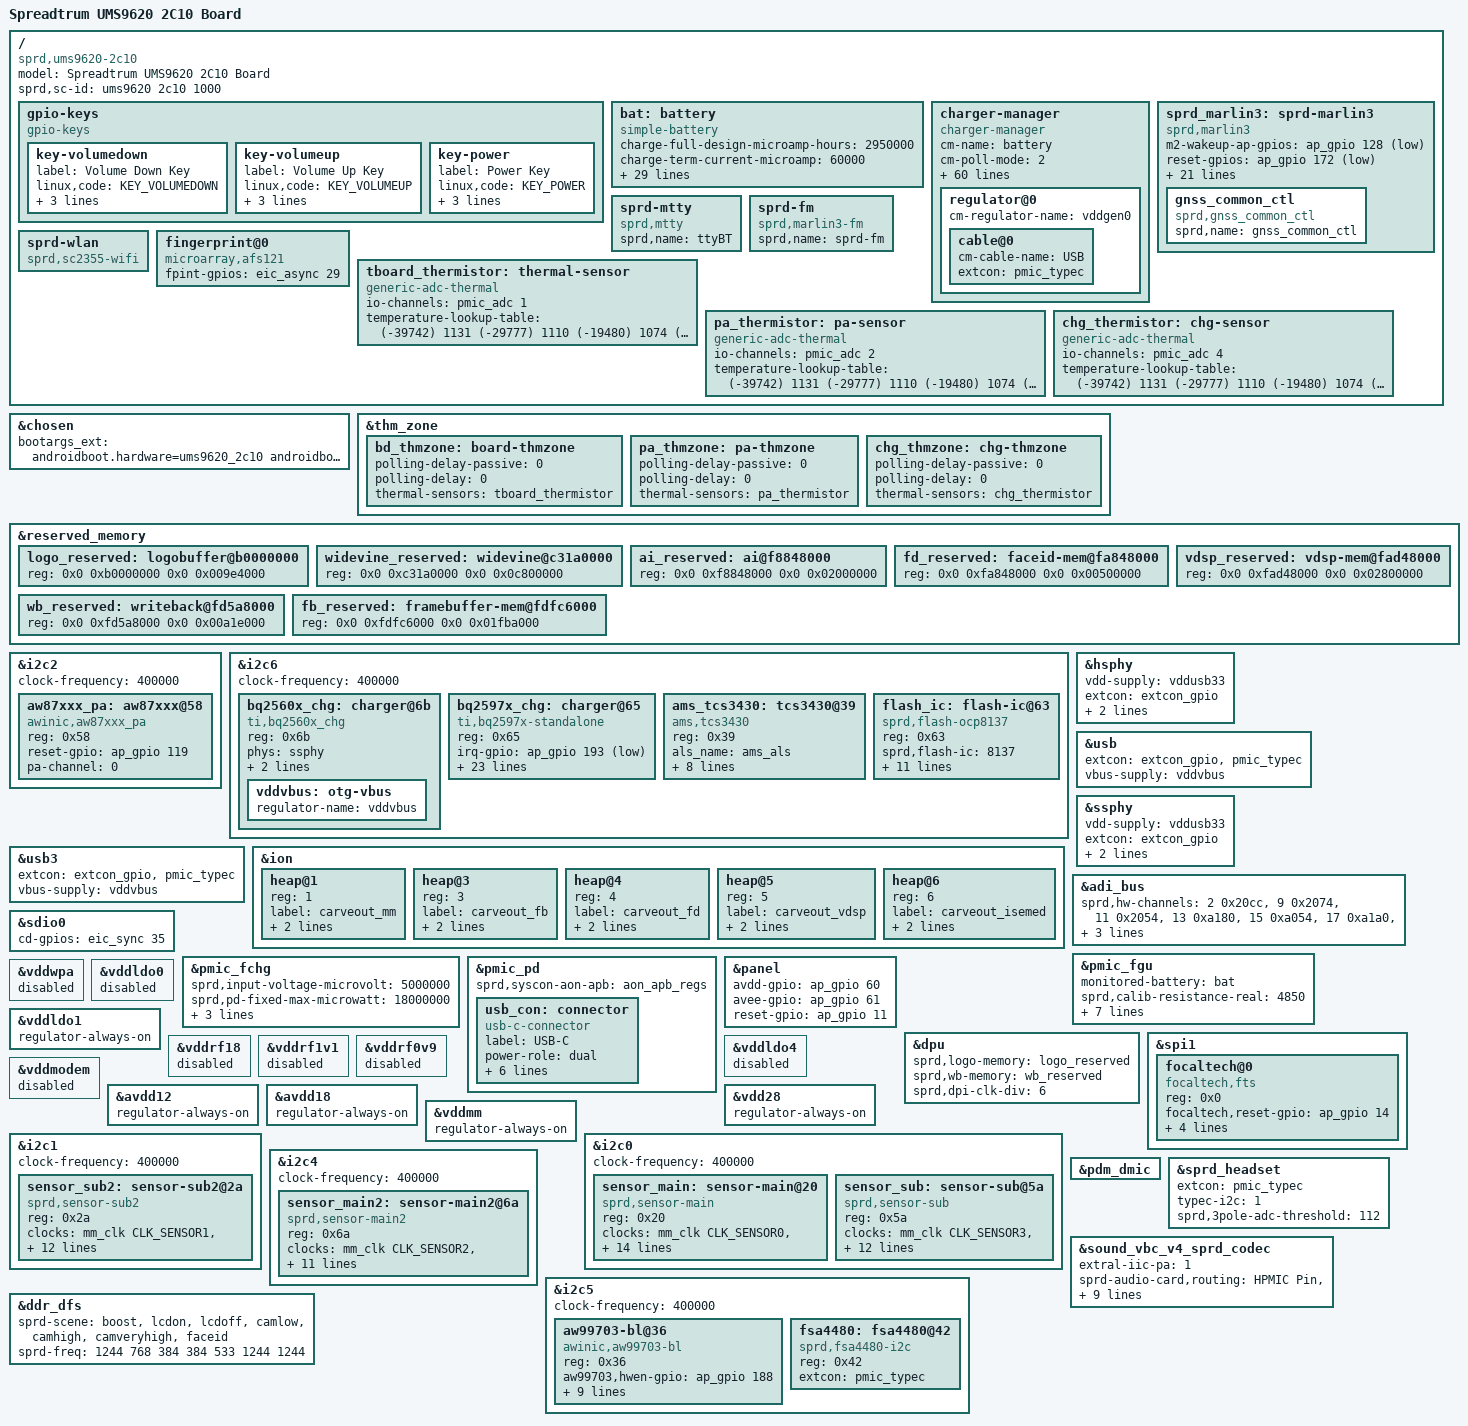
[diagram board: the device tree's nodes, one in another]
/dts-v1/;
/plugin/;
#include <dt-bindings/input/input.h>
#include <dt-bindings/gpio/gpio.h>
#include <dt-bindings/interrupt-controller/arm-gic.h>
#include <dt-bindings/clock/sprd,ums9620-clk.h>
#include <dt-bindings/usb/pd.h>
#include "lcd/lcd_ft8756_txd_mipi_hdplus.dtsi"
#include "lcd/lcd_jd9365t_cpt_mipi_hdp.dtsi"
#include "lcd/lcd_nl9911c_truly_mipi_hdp.dtsi"
#include "lcd/lcd_dummy_mipi.dtsi"
#include <dt-bindings/mfd/sprd,ump9620-regs.h>
#include <dt-bindings/mfd/sprd,ump9620-mask.h>
/ {

	model = "Spreadtrum UMS9620 2C10 Board";

	compatible = "sprd,ums9620-2c10";

	sprd,sc-id = "ums9620 2c10 1000";

	fragment {
		target-path = "/";
		__overlay__ {

			gpio-keys {
				compatible = "gpio-keys";

				key-volumedown {
					label = "Volume Down Key";
					linux,code = <KEY_VOLUMEDOWN>;
					gpios = <&ap_gpio 7 GPIO_ACTIVE_LOW>;
					debounce-interval = <2>;
					wakeup-source;
				};

				key-volumeup {
					label = "Volume Up Key";
					linux,code = <KEY_VOLUMEUP>;
					gpios = <&pmic_eic 4 GPIO_ACTIVE_HIGH>;
					debounce-interval = <2>;
					wakeup-source;
				};

				key-power {
					label = "Power Key";
					linux,code = <KEY_POWER>;
					gpios = <&pmic_eic 1 GPIO_ACTIVE_LOW>;
					debounce-interval = <2>;
					wakeup-source;
				};
			};

			bat: battery {
				compatible = "simple-battery";
				charge-full-design-microamp-hours = <2950000>;
				charge-term-current-microamp = <60000>;
				constant_charge_voltage_max_microvolt = <4340000>;
				factory-internal-resistance-micro-ohms = <252000>;
				voltage-min-design-microvolt = <3450000>;
				fast-charge-threshold-microvolt = <4100000>;
				ocv-capacity-celsius = <20>;
				ocv-capacity-table-0 = <4313000 100>, <4254000 95>, <4201000 90>,
							<4151000 85>, <4102000 80>, <4060000 75>,
							<4006000 70>, <3973000 65>, <3930000 60>,
							<3882000 55>, <3851000 50>, <3829000 45>,
							<3810000 40>, <3795000 35>, <3781000 30>,
							<3765000 25>, <3746000 20>, <3722000 15>,
							<3694000 10>, <3682000 5>, <3400000 0>;
				voltage-temp-table = <1084000 800>, <975000 850>, <868000 900>,
							  <765000 950>, <668000 1000>, <580000 1050>,
							  <501000 1100>, <430000 1150>, <369000 1200>,
							  <315000 1250>, <270000 1300>, <231000 1350>,
							  <197000 1400>, <169000 1450>, <145000 1500>,
							  <125000 1550>, <108000 1600>, <93000 1650>;
				capacity-temp-table = <45 100>, <25 100>, <10 100>, <0 95>, <(-10) 90>;
				resistance-temp-table = <45 53>, <25 100>, <10 395>, <0 567>, <(-10) 793>;
				charge-sdp-current-microamp = <500000 500000>;
				charge-dcp-current-microamp = <2000000 2500000>;
				charge-cdp-current-microamp = <1500000 1500000>;
				charge-unknown-current-microamp = <500000 500000>;
				charge-fchg-current-microamp = <3000000 2000000>;
				charge-flash-current-microamp = <5000000 2700000>;
			};

			charger-manager {
				compatible = "charger-manager";
				cm-name = "battery";
				cm-poll-mode = <2>;
				cm-poll-interval = <15000>;
				cm-battery-stat = <2>;

				cm-fullbatt-vchkdrop-ms = <30000>;
				cm-fullbatt-vchkdrop-volt = <60000>;
				cm-fullbatt-voltage = <4300000>;
				cm-fullbatt-current = <120000>;
				cm-fullbatt-capacity = <100>;
				/*Charge pump target charge current*/
				cm-cp-taper-current = <1000000>;

				cm-chargers = "bq2560x_charger";
				cm-charge-pumps = "bq2597x-standalone";
				cm-fast-chargers = "sc2730_fast_charger";
				cm-fuel-gauge = "sc27xx-fgu";

				/* in deci centigrade */
				cm-battery-cold = <200>;
				cm-battery-cold-in-minus;
				cm-battery-hot = <800>;
				cm-battery-temp-diff = <100>;

				/* Allow charging for 6hr */
				cm-charging-max = <21600000>;
				/* recovery charging after stop charging 45min */
				cm-discharging-max = <2700000>;

				/* the interval to feed charger watchdog */
				cm-wdt-interval = <60>;

				/* drop voltage in microVolts to allow shutdown */
				cm-shutdown-voltage = <3100000>;

				/* when 99% of the time is exceeded, it will be forced to 100% */
				cm-tickle-time-out = <1500>;

				/* how much time to allow capacity change */
				cm-one-cap-time = <30>;

				/* cm-thermal-zone = "board-thmzone"; */

				/* when the safe charging voltage is exceeded, stop charging */
				cm-charge-voltage-max = <6500000>;
				cm-fast-charge-voltage-max = <10500000>;
				cm-flash-charge-voltage-max = <12000000>;
				/* drop voltage in microVolts to restart charging */
				cm-charge-voltage-drop = <700000>;
				cm-fast-charge-voltage-drop = <700000>;
				cm-flash-charge-voltage-drop = <1000000>;

				cm-dcp-jeita-temp-table = <1000 1030 0 4340000>, <1150 1180 700000 4340000>,
					<1450 1420 2000000 4340000>, <1600 1570 700000 4100000>;
				cm-sdp-jeita-temp-table = <1000 1030 0 4340000>, <1150 1180 500000 4340000>,
					<1450 1420 500000 4340000>, <1600 1570 500000 4100000>;
				cm-cdp-jeita-temp-table = <1000 1030 0 4340000>, <1150 1180 700000 4340000>,
					<1450 1420 1500000 4340000>, <1600 1570 700000 4100000>;
				cm-unknown-jeita-temp-table = <1000 1030 0 4340000>, <1150 1180 500000 4340000>,
					<1450 1420 500000 4340000>, <1600 1570 500000 4100000>;
				cm-fchg-jeita-temp-table = <1000 1030 0 4340000>, <1150 1180 700000 4340000>,
					<1450 1420 3250000 4340000>, <1600 1570 700000 4100000>;
				cm-flash-jeita-temp-table = <1000 1030 0 4340000>, <1150 1180 1000000 4340000>,
					<1450 1420 5000000 4340000>, <1600 1570 1000000 4100000>;

				cm-cap-remap-table = <1 2 3>, <2 3 2>, <98 99 2>, <99 100 3>;

				monitored-battery = <&bat>;

				cm-ir-cv-offset-microvolt = <100000>;
				cm-ir-rc = <20>;
				cm-ir-us-upper-limit-microvolt = <4500000>;

				regulator@0 {
					cm-regulator-name = "vddgen0";
					cable@0 {
						cm-cable-name = "USB";
						extcon = <&pmic_typec>;
					};
				};
			};

			sprd_marlin3: sprd-marlin3 {
				compatible = "sprd,marlin3";
				m2-wakeup-ap-gpios = <&ap_gpio 128 GPIO_ACTIVE_LOW>;
				reset-gpios = <&ap_gpio 172 GPIO_ACTIVE_LOW>;
				enable-gpios = <&ap_gpio 171 GPIO_ACTIVE_LOW>;
				m2-to-ap-irq-gpios = <&ap_gpio 173 GPIO_ACTIVE_LOW>;
				xtal-26m-clk-type = "TCXO";
				avdd12-supply = <&vddwcn>;
				avdd33-supply = <&vddwifipa>;
				dcxo18-supply = <&vddsim2>;

				clock-names = "clk_32k","source","enable";
				clocks = <&aonapb_gate CLK_AUX0>,
					 <&ext_32k>,
					 <&aonapb_gate CLK_AUX0_EB>;

				sdhci-name = <&sdio1>;
				sprd,btwf-file-name = "/dev/block/by-name/wcnmodem";
				sprd,gnss-file-name = "/dev/block/by-name/gnssmodem";
				adma-tx;
				adma-rx;
				/*
				 * bound parameter:
				 * [0]:addr offset, [1]:mask, [2]:unboundval, [3]:boundval
				 */
				avdd12-parent-bound-chip = <REG_ANA_SLP_DCDC_PD_CTRL MASK_ANA_SLP_DCDCGEN1_PD_EN 0x0 MASK_ANA_SLP_DCDCGEN1_PD_EN>;
				avdd12-bound-wbreq = <REG_ANA_LDO_XTL_EN10 MASK_ANA_LDO_VDDWCN_EXT_XTL3_EN 0x0 MASK_ANA_LDO_VDDWCN_EXT_XTL3_EN>;
				avdd33-bound-wbreq = <REG_ANA_LDO_XTL_EN11 MASK_ANA_LDO_VDDWIFIPA_EXT_XTL3_EN 0x0 MASK_ANA_LDO_VDDWIFIPA_EXT_XTL3_EN>;

				gnss_common_ctl {
					compatible = "sprd,gnss_common_ctl";
					sprd,name = "gnss_common_ctl";
				};
			};

			sprd-mtty {
				compatible = "sprd,mtty";
				sprd,name = "ttyBT";
			};

			sprd-fm {
				compatible = "sprd,marlin3-fm";
				sprd,name = "sprd-fm";
			};

			sprd-wlan{
				compatible = "sprd,sc2355-wifi";
			};

			fingerprint@0 {
				compatible = "microarray,afs121";
				fpint-gpios = <&eic_async 29 0>;
			};

			tboard_thermistor: thermal-sensor {
				compatible = "generic-adc-thermal";
				#thermal-sensor-cells = <0>;
				io-channels = <&pmic_adc 1>;
				io-channel-names = "sensor-channel";
				temperature-lookup-table = <
					(-39742) 1131
					(-29777) 1110
					(-19480) 1074
					(-4679) 983
					10110 838
					24805 654
					44922 413
					54903 316
					64895 238
					74884 178
					84883 133
					94883 100
					104880 75
					114889 57
					124872 43 >;
			};

			pa_thermistor: pa-sensor {
				compatible = "generic-adc-thermal";
				#thermal-sensor-cells = <0>;
				io-channels = <&pmic_adc 2>;
				io-channel-names = "sensor-channel";
				temperature-lookup-table = <
					(-39742) 1131
					(-29777) 1110
					(-19480) 1074
					(-4679) 983
					10110 838
					24805 654
					44922 413
					54903 316
					64895 238
					74884 178
					84883 133
					94883 100
					104880 75
					114889 57
					124872 43 >;
			};

			chg_thermistor: chg-sensor {
				compatible = "generic-adc-thermal";
				#thermal-sensor-cells = <0>;
				io-channels = <&pmic_adc 4>;
				io-channel-names = "sensor-channel";
				temperature-lookup-table = <
					(-39742) 1131
					(-29777) 1110
					(-19480) 1074
					(-4679) 983
					10110 838
					24805 654
					44922 413
					54903 316
					64895 238
					74884 178
					84883 133
					94883 100
					104880 75
					114889 57
					124872 43 >;
			};
		};
	};
};

&chosen {
	bootargs_ext = "androidboot.hardware=ums9620_2c10 androidboot.dtbo_idx=0";
};

&thm_zone {
	bd_thmzone: board-thmzone {
		polling-delay-passive = <0>;
		polling-delay = <0>;
		thermal-sensors = <&tboard_thermistor>;
	};

	pa_thmzone: pa-thmzone {
		polling-delay-passive = <0>;
		polling-delay = <0>;
		thermal-sensors = <&pa_thermistor>;
	};

	chg_thmzone: chg-thmzone {
		polling-delay-passive = <0>;
		polling-delay = <0>;
		thermal-sensors = <&chg_thermistor>;
	};
};

&reserved_memory {
	logo_reserved: logobuffer@b0000000 {
		reg = <0x0 0xb0000000 0x0 0x009e4000>;
	};

	widevine_reserved: widevine@c31a0000 {
		reg = <0x0 0xc31a0000 0x0 0x0c800000>;
	};

	ai_reserved: ai@f8848000 {
		reg = <0x0 0xf8848000 0x0 0x02000000>;
	};

	fd_reserved: faceid-mem@fa848000 {
		reg = <0x0 0xfa848000 0x0 0x00500000>;
	};

	vdsp_reserved: vdsp-mem@fad48000 {
		reg = <0x0 0xfad48000 0x0 0x02800000>;
	};

	wb_reserved: writeback@fd5a8000 {
		reg = <0x0 0xfd5a8000 0x0 0x00a1e000>;
	};

	fb_reserved: framebuffer-mem@fdfc6000 {
		reg = <0x0 0xfdfc6000 0x0 0x01fba000>;
	};
};

&i2c2 {
	status = "okay";
	clock-frequency = <400000>;

	aw87xxx_pa: aw87xxx@58 {
		compatible = "awinic,aw87xxx_pa";
		reg = <0x58>;
		reset-gpio = <&ap_gpio 119 GPIO_ACTIVE_HIGH>;
		pa-channel = <0>;
		status = "okay";
	};
};

&i2c6 {
	status = "okay";
	clock-frequency = <400000>;

	bq2560x_chg: charger@6b {
		compatible = "ti,bq2560x_chg";
		reg = <0x6b>;
		phys = <&ssphy>;
		monitored-battery = <&bat>;
		extcon = <&extcon_gpio>;
		vddvbus:otg-vbus {
			regulator-name = "vddvbus";
		};
	};

	bq2597x_chg: charger@65 {
		compatible = "ti,bq2597x-standalone";
		reg = <0x65>;
		irq-gpio = <&ap_gpio 193 GPIO_ACTIVE_LOW>;

		ti,bq2597x,bus-therm-disable = <1>;
		ti,bq2597x,regulation-disable = <1>;

		ti,bq2597x,bat-ovp-threshold = <4400>;
		ti,bq2597x,bat-ovp-alarm-threshold = <4340>;
		ti,bq2597x,bat-ocp-threshold = <5500>;
		ti,bq2597x,bat-ocp-alarm-threshold = <5000>;
		ti,bq2597x,bus-ovp-threshold = <11500>;
		ti,bq2597x,bus-ovp-alarm-threshold = <10500>;
		ti,bq2597x,bus-ocp-threshold = <3000>;
		ti,bq2597x,bus-ocp-alarm-threshold = <2700>;
		ti,bq2597x,bat-ucp-alarm-threshold = <1000>;
		ti,bq2597x,bat-therm-threshold = <0x15>;
		ti,bq2597x,bus-therm-threshold = <0x15>;
		ti,bq2597x,die-therm-threshold = <0xc8>;
		ti,bq2597x,ac-ovp-threshold = <11>;
		ti,bq2597x,sense-resistor-mohm = <5>;
		ti,bq2597x,adc-sample-bits = <13>;
		ti,bq2597x,ibat-regulation-threshold = <300>;
		ti,bq2597x,vbat-regulation-threshold = <100>;
		ti,bq2597x,vdrop-threshold = <400>;
		ti,bq2597x,vdrop-deglitch = <5000>;
		ti,bq2597x,ss-timeout = <100000>;
		ti,bq2597x,watchdog-timer = <30000>;
	};

	ams_tcs3430: tcs3430@39 {
		compatible = "ams,tcs3430";
		reg = <0x39>;
		als_name = "ams_als";
		persist = <0>;
		als_time_ms = <100>;
		als_gain = <64>;
		int_config = <0>;
		als_can_wake = <1>;
		irq_gpios = <60>;
		interrupt-parent = <&ap_gpio>;
		interrupts = <60 IRQ_TYPE_LEVEL_LOW>;
	};
};

&hsphy {
	vdd-supply = <&vddusb33>;
	extcon = <&extcon_gpio>;
	sprd,hsphy-device-eye-pattern = <0x067bd1c0>;
	sprd,hsphy-host-eye-pattern = <0x067bd1c0>;
	status = "okay";
};

&usb {
	extcon = <&extcon_gpio>, <&pmic_typec>;
	vbus-supply = <&vddvbus>;
	status = "okay";
};

&ssphy {
	vdd-supply = <&vddusb33>;
	extcon = <&extcon_gpio>;
	sprd,hsphy-device-eye-pattern = <0x067bd1c0>;
	sprd,hsphy-host-eye-pattern = <0x067bd1c0>;
	status = "okay";
};

&usb3 {
	extcon = <&extcon_gpio>, <&pmic_typec>;
	vbus-supply = <&vddvbus>;
	status = "okay";
};

&ion {
	heap@1 {
		reg = <1>;
		label = "carveout_mm";
		type = <2>;
		memory-region = <&widevine_reserved>;
	};

	heap@3 {
		reg = <3>;
		label = "carveout_fb";
		type = <2>;
		memory-region = <&fb_reserved>;
	};

	heap@4 {
		reg = <4>;
		label = "carveout_fd";
		type = <2>;
		memory-region = <&fd_reserved>;
	};

	heap@5 {
		reg = <5>;
		label = "carveout_vdsp";
		type = <2>;
		memory-region = <&vdsp_reserved>;
	};

	heap@6 {
		reg = <6>;
		label = "carveout_isemed";
		type = <2>;
		memory-region = <&ise_med_reserved>;
	};
};

&adi_bus {
	sprd,hw-channels = <2 0x20cc>, <9 0x2074>, <11 0x2054>, <13 0xa180>,
			<15 0xa054>, <17 0xa1a0>, <19 0xa044>, <21 0xa0e8>,
			<23 0x244c>, <25 0xa074>, <27 0x2044>, <30 0x2020>,
			<34 0x21b8>, <35 0x21ac>, <32 0x217c>, <33 0x2188>;
};

&sdio0 {
	cd-gpios = <&eic_sync 35 GPIO_ACTIVE_HIGH>;
};

&pmic_fgu {
	monitored-battery = <&bat>;
	sprd,calib-resistance-real = <4850>;
	sprd,calib-resistance-spec = <20000>;
	first-calib-voltage = <3580000>;
	first-calib-capacity = <50>;
	fgu-capacity-track;
	fullbatt-track-end-vol = <4295>;
	fullbatt-track-end-cur = <130>;
	phys = <&hsphy>;
};

&pmic_fchg {
	sprd,input-voltage-microvolt = <5000000>;
	sprd,pd-fixed-max-microwatt = <18000000>;
	sprd,support-sfcp;
	sprd,support-pd-pps;
	phys = <&ssphy>;
};

&pmic_pd {
	status = "okay";
	sprd,syscon-aon-apb = <&aon_apb_regs>;
	usb_con: connector {
		compatible = "usb-c-connector";
		label = "USB-C";
		power-role = "dual";
		try-power-role = "sink";
		source-pdos = <PDO_FIXED(5000, 400, PDO_FIXED_USB_COMM)>;
		sink-pdos = <PDO_FIXED(5000, 3000, PDO_FIXED_USB_COMM)
				PDO_PPS_APDO(3300, 11000, 3000)>;
		op-sink-microwatt = <10000000>;
	};
};

&panel {
	avdd-gpio = <&ap_gpio 60 GPIO_ACTIVE_HIGH>;
	avee-gpio = <&ap_gpio 61 GPIO_ACTIVE_HIGH>;
	reset-gpio = <&ap_gpio 11 GPIO_ACTIVE_HIGH>;
};

&dpu {
	sprd,logo-memory = <&logo_reserved>;
	sprd,wb-memory = <&wb_reserved>;
	sprd,dpi-clk-div = <6>;
};

&spi1 {
	status = "okay";

	focaltech@0 {
		compatible = "focaltech,fts";
		reg = <0x0>;
		focaltech,reset-gpio = <&ap_gpio 14 GPIO_ACTIVE_HIGH>;
		focaltech,irq-gpio = <&ap_gpio 13 GPIO_ACTIVE_HIGH>;
		focaltech,max-touch-number = <5>;
		focaltech,display-coords =  <0 0 1080 2400>;
		spi-max-frequency = <6000000>;
	};
};

&vddwpa {
	status = "disabled";
};

&vddldo0 {
	status = "disabled";
};

&vddldo1 {
	regulator-always-on;
};

&vddrf18 {
	status = "disabled";
};

&vddrf1v1 {
	status = "disabled";
};

&vddrf0v9 {
	status = "disabled";
};

&vddldo4 {
	status = "disabled";
};

&vddmodem {
	status = "disabled";
};

&avdd12 {
	regulator-always-on;
};

&avdd18 {
	regulator-always-on;
};

&vdd28 {
	regulator-always-on;
};

&vddmm {
	regulator-always-on;
};

&i2c0 {
	status = "okay";
	clock-frequency = <400000>;

	sensor_main: sensor-main@20 {
		compatible = "sprd,sensor-main";
		reg = <0x20>;
		clock-names = "clk_src","sensor_eb",
			"clk_96m","clk_64m",
			"clk_51m2","clk_48m","clk_26m";
		clocks = <&mm_clk CLK_SENSOR0>,<&mm_gate CLK_SENSOR0_EN>,
				<&g5l_pll CLK_TGPLL_96M>,<&g5l_pll CLK_TGPLL_64M>,
				<&g5l_pll CLK_TGPLL_51M2>,<&g5l_pll CLK_TGPLL_48M>,<&ext_26m>;
		vddio-supply = <&vddcamio>;
		vddcama-supply = <&vddcama0>;
		vddcamd-supply = <&vddcamd0>;
		vddcammot-supply = <&vddcammot0>;
		avdd-gpios = <&ap_gpio 80 0>;
		reset-gpios = <&ap_gpio 40 0>;
		power-down-gpios = <&ap_gpio 46 0>;
		sprd,phyid = <3>;
		csi = <&csi3>;
	};

	sensor_sub: sensor-sub@5a {
		compatible = "sprd,sensor-sub";
		reg = <0x5a>;
		clock-names = "clk_src","sensor_eb",
			"clk_96m","clk_64m",
			"clk_51m2","clk_48m","clk_26m";
		clocks = <&mm_clk CLK_SENSOR3>,<&mm_gate CLK_SENSOR3_EN>,
			<&g5l_pll CLK_TGPLL_96M>,<&g5l_pll CLK_TGPLL_64M>,
			<&g5l_pll CLK_TGPLL_51M2>,<&g5l_pll CLK_TGPLL_48M>,<&ext_26m>;
		vddio-supply = <&vddcamio>;
		avdd-gpios = <&ap_gpio 80 0>;
		vddcamd-supply = <&vddcamd1>;
		reset-gpios = <&ap_gpio 39 0>;
		power-down-gpios = <&ap_gpio 45 0>;
		sprd,phyid = <2>;
		csi = <&csi2>;
	};
};

&i2c1 {
	status = "okay";
	clock-frequency = <400000>;

	sensor_sub2: sensor-sub2@2a {
		compatible = "sprd,sensor-sub2";
		reg = <0x2a>;
		clock-names = "clk_src","sensor_eb",
			"clk_96m","clk_64m",
			"clk_51m2","clk_48m","clk_26m";
		clocks = <&mm_clk CLK_SENSOR1>,<&mm_gate CLK_SENSOR1_EN>,
			<&g5l_pll CLK_TGPLL_96M>,<&g5l_pll CLK_TGPLL_64M>,
			<&g5l_pll CLK_TGPLL_51M2>,<&g5l_pll CLK_TGPLL_48M>,<&ext_26m>;
		vddio-supply = <&vddcamio>;
		avdd-gpios = <&ap_gpio 79 0>;
		vddcamd-supply = <&vddcamd2>;
		mot-gpios = <&ap_gpio 78 0>;
		reset-gpios = <&ap_gpio 41 0>;
		sprd,phyid = <0>;/*6*/
		csi = <&csi0>;
	};
};

&i2c4 {
	status = "okay";
	clock-frequency = <400000>;
	sensor_main2: sensor-main2@6a {
		compatible = "sprd,sensor-main2";
		reg = <0x6a>;
		clock-names = "clk_src","sensor_eb",
			"clk_96m","clk_64m",
			"clk_51m2","clk_48m","clk_26m";
		clocks = <&mm_clk CLK_SENSOR2>,<&mm_gate CLK_SENSOR2_EN>,
			<&g5l_pll CLK_TGPLL_96M>,<&g5l_pll CLK_TGPLL_64M>,
			<&g5l_pll CLK_TGPLL_51M2>,<&g5l_pll CLK_TGPLL_48M>,<&ext_26m>;
		vddio-supply = <&vddcamio>;
		avdd-gpios = <&ap_gpio 79 0>;
		reset-gpios = <&ap_gpio 44 0>;
		power-down-gpios = <&ap_gpio 50 0>;
		sprd,phyid = <1>;/*6*/
		csi = <&csi1>;
	};
};

&i2c5 {
	status = "okay";
	clock-frequency = <400000>;

	aw99703-bl@36 {
		compatible = "awinic,aw99703-bl";
		reg = <0x36>;
		aw99703,hwen-gpio = <&ap_gpio 188 GPIO_ACTIVE_HIGH>;
		aw99703,pwm-mode = <0>;
		aw99703,using-lsb;
		aw99703,bl-fscal-led = <0x13>;
		aw99703,turn-on-ramp = <0x09>;
		aw99703,turn-off-ramp = <0x09>;
		aw99703,pwm-trans-dim = <0>;
		aw99703,i2c-trans-dim = <0x07>;
		aw99703,bl-channel = <2>;
		aw99703,bl-map = <3>;
	};

	fsa4480: fsa4480@42 {
		compatible = "sprd,fsa4480-i2c";
		reg = <0x42>;
		extcon = <&pmic_typec>;
	};
};

&i2c6 {
	status = "okay";
	clock-frequency = <400000>;

	flash_ic: flash-ic@63 {
		compatible = "sprd,flash-ocp8137";
		reg = <0x63>;
		sprd,flash-ic = <8137>;
		sprd,torch = <1>;
		sprd,preflash = <1>;
		sprd,highlight = <1>;
		sprd,torch-level = <128>;
		sprd,preflash-level = <128>;
		sprd,highlight-level = <128>;
		sprd,lvfm-enable = <1>;
		flash-torch-en-gpios = <&ap_gpio 112 0>;
		flash-chip-en-gpios = <&ap_gpio 119 0>;
		flash-en-gpios = <&ap_gpio 111 0>;
		flash-sync-gpios = <&ap_gpio 59 0>;
	};
};


&pdm_dmic {
	status = "okay";
};

&sprd_headset {
	status = "okay";
	extcon = <&pmic_typec>;
	typec-i2c = <1>;
	sprd,3pole-adc-threshold = <112>;
};

&sound_vbc_v4_sprd_codec {
	status = "okay";
	extral-iic-pa = <1>;
	sprd-audio-card,routing =
		"HPMIC Pin", "HP Mic Jack",
		"MIC Pin", "Mic Jack",
		"MIC2 Pin", "Aux Mic Jack",
		"MIC3 Pin", "Aux Mic2 Jack",
		"HeadPhone Jack", "HP Pin",
		"Ext Spk", "SPK Pin",
		"UCP1301 SPK ON", "SPK Pin",
		"Ext Spk", "UCP1301 SPK",
		"PDM DMIC2 ON", "SPK Pin",
		"Ext Spk", "PDM_DMIC2",
		"DMIC Pin", "DMic Jack",
		"DMIC1 Pin", "DMic1 Jack",
		"Ext Ear", "EAR Pin",
		"UCP1301 RCV ON", "EAR Pin",
		"Ext Ear", "UCP1301 RCV";
};

&ddr_dfs {
	  sprd-scene = "boost", "lcdon", "lcdoff", "camlow",
			"camhigh", "camveryhigh", "faceid";
	  sprd-freq = <1244 768 384 384 533 1244 1244>;
};
